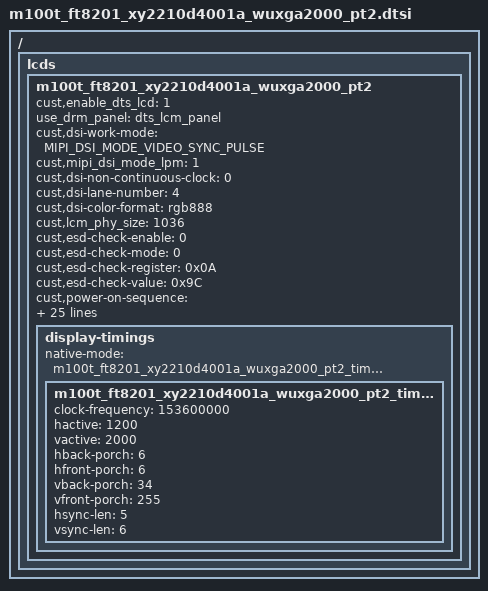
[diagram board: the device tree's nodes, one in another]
#include <dt-bindings/display/cust_drm.h>

/ {
	fragment {
		target-path = "/";
		__overlay__ {
			lcds {
				m100t_ft8201_xy2210d4001a_wuxga2000_pt2: m100t_ft8201_xy2210d4001a_wuxga2000_pt2 {

					cust,enable_dts_lcd=<1>; //use lcd dts
					use_drm_panel="dts_lcm_panel";
					cust,dsi-work-mode = <MIPI_DSI_MODE_VIDEO_SYNC_PULSE>;
					cust,mipi_dsi_mode_lpm=<1>;
					cust,dsi-non-continuous-clock=<0>;
					cust,dsi-lane-number = <4>;
					cust,dsi-color-format = "rgb888";

					cust,lcm_phy_size=<1036>;
					/*cust,width-mm = <108>;
					cust,height-mm = <172>;*/

					cust,esd-check-enable = <0>;
					cust,esd-check-mode = <0>;
					cust,esd-check-register = <0x0A>;
					cust,esd-check-value = <0x9C>;

					/*<cust_gpio_type enable_level delay>*/
					cust,power-on-sequence = <CUST_GPIO_LCM_1V8 HIGH 10>,
											<CUST_GPIO_BIAS_POS HIGH 1>, 
											<CUST_GPIO_BIAS_NEG HIGH 20>,
											<CUST_GPIO_TP_RST LOW 1>,
											<CUST_GPIO_TP_RST HIGH 1>,
											<CUST_GPIO_LCM_RST HIGH 10>,
											<CUST_GPIO_LCM_RST LOW 2>,
											<CUST_GPIO_LCM_RST HIGH 5>;

					cust,power-on-sequence_after_cmd=<CUST_GPIO_BIAS_EN HIGH 0>;

					cust,power-off-sequence = <CUST_GPIO_BIAS_EN LOW 0>,
											<CUST_GPIO_TP_RST LOW 10>, 
											<CUST_GPIO_LCM_1V8 LOW 10>,
											<CUST_GPIO_BIAS_POS LOW 2>,
											<CUST_GPIO_BIAS_NEG LOW 0>;
											
					/*cust,power-off-sequence_before_cmd= <CUST_GPIO_BIAS_EN LOW 0>;*/
					
					/*dely SizeH SizeL Cmd Data */
					cust,initial-command = [
						00 02 50 5a 
						00 02 54 03 
						00 03 50 5a 03 
						00 02 80 ee 
						00 03 50 5a 08 
						00 03 80 c8 00 
						00 03 50 5a 09 
						00 11 80 5a 51 b5 2a 6c d5 4a 01 80 e0 cd f3 3c 0f 00 b7 
						00 11 90 00 3f 42 0a e3 6d db f0 91 5c 62 20 6b a1 26 00 
						00 07 a0 01 82 08 20 06 00 
						00 03 50 5a 0a 
						00 11 80 a5 4b 03 00 1c 30 48 5f 72 7c b1 b4 ef 4a 18 6a 
						00 11 90 43 43 36 2a 1c 16 17 00 1c 30 48 5f 72 7c b1 b4 
						00 0d a0 ef 4a 18 6a 43 43 36 2a 1c 16 03 00 
						00 03 50 5a 0b 
						00 11 80 00 00 20 44 08 00 60 47 00 00 10 22 04 00 b0 23 
						00 03 90 15 00 
						00 03 50 5a 0c 
						00 11 80 fe 68 58 82 3e 64 b8 06 00 60 15 00 50 15 56 51 
						00 11 90 15 55 61 15 00 60 15 00 50 15 56 51 15 55 61 95 
						00 11 a0 ab 18 00 05 00 05 00 05 80 4c 29 84 52 01 09 00 
						00 03 50 5a 0d 
						00 0f 80 f0 b1 71 ef 49 c0 80 1a 00 00 00 00 00 00 
						00 03 50 5a 0e 
						00 0d 80 ff 81 68 ec 22 6d 22 00 00 00 00 00 
						00 03 50 5a 0f 
						00 11 80 0d 08 4a 00 25 80 64 0c 51 11 c8 50 01 42 8c 8c 
						00 08 90 24 69 81 71 44 7c 14 
						00 03 50 5a 10 
						00 11 80 00 78 03 e7 1f 17 00 78 20 d3 d4 18 30 88 41 8a 
						00 10 90 39 28 a9 c5 9a 7b fa 07 7e e0 07 7e 20 10 00 
						00 03 50 5a 11 
						00 11 80 46 77 03 40 ca f3 ff 83 30 08 c4 06 a1 d8 24 18 
						00 11 90 30 c6 66 c1 80 31 15 cb e5 d2 68 6c 36 1d 04 c8 
						00 11 a0 b0 d9 88 60 b0 81 40 1a 1b 48 63 03 b9 00 1c 80 
						00 11 b0 50 30 00 e0 e1 01 00 28 0e 06 43 55 55 55 55 55 
						00 11 c0 95 88 88 88 88 88 c8 08 86 c6 e3 81 00 20 00 21 
						00 11 d0 42 88 00 00 00 00 40 00 00 31 04 41 06 00 00 00 
						00 11 e0 00 00 00 00 00 00 00 00 00 00 92 04 00 85 11 0c 
						00 0a f0 00 00 40 00 00 00 00 5e 00 
						00 03 50 5a 12 
						00 11 80 00 00 00 00 00 00 00 00 00 00 00 00 00 00 00 00 
						00 0a 90 00 00 00 00 00 00 00 74 00 
						00 03 50 5a 13 
						00 11 80 01 00 00 0c 00 00 00 00 01 02 01 01 44 0c ce e7 
						00 04 90 62 06 00 
						00 03 50 5a 14 
						00 11 80 d1 00 40 5e e9 ef f7 fb fd 7e 01 00 00 f4 c5 41 
						00 11 90 88 1c 60 0e 42 e4 00 9b 10 22 07 80 8b 10 39 80 
						00 11 a0 39 e4 c8 08 cc 80 21 45 00 00 00 00 00 00 00 00 
						00 11 b0 00 00 00 00 00 00 10 00 00 ec be e8 1b 00 40 a1 
						00 11 c0 50 b8 01 21 72 80 31 00 37 21 44 0e 30 06 e0 46 
						00 11 d0 84 c8 01 c6 00 dc 8c 10 39 c0 18 80 1b 12 22 07 
						00 11 e0 18 03 70 53 42 e4 00 63 00 dc 04 8e 1c 60 0c 80 
						00 11 f0 7b c0 91 07 8c 01 18 01 bf 5f 08 00 00 00 00 00 
						00 03 50 5a 15 
						00 11 80 00 00 00 00 00 00 00 00 00 00 00 00 52 d4 e0 e7 
						00 11 90 f3 00 e8 63 41 c8 80 86 60 40 1d 31 32 a0 21 18 
						00 11 a0 50 00 00 00 00 00 00 00 00 00 00 00 00 00 00 00 
						00 11 b0 00 00 00 00 00 00 00 40 13 00 f0 00 94 b6 6d db 
						00 11 c0 b6 6d db 95 92 3e 4e 41 0c 42 00 a0 b6 6d db b6 
						00 11 d0 6d db b6 5d ab e8 e3 82 a1 38 92 65 6a db b6 6d 
						00 11 e0 db b6 6d db b5 9a 3e 6e 49 8e 62 08 a2 b6 6d db 
						00 11 f0 b6 6d db b6 5d 29 e8 e3 00 81 30 10 45 6a 5b 00 
						00 03 50 5a 16 
						00 11 80 00 00 00 00 00 00 00 00 00 00 00 00 00 00 00 00 
						00 07 90 00 00 00 00 90 40 
						00 03 50 5a 18 
						00 11 80 ef bd f7 de 7b ef bd 07 08 08 0a 0c 0c 0c 0c 0c 
						00 11 90 0c 0c 0c 5c 09 a8 aa aa aa aa aa aa aa aa aa 5a 
						00 11 a0 59 59 59 59 59 59 59 59 59 59 59 09 04 ff 05 80 
						00 10 b0 80 00 04 20 00 01 08 40 00 02 10 80 00 04 0f 
						00 03 50 5a 19 
						00 11 80 eb d6 b9 b3 a8 9d 98 91 8c 87 84 82 66 f6 ff ff 
						00 11 90 ff ff ff ff ff 7f 0f 0f af b5 71 0e 6c 4a 69 08 
						00 08 a0 00 04 62 00 00 00 00 
						00 03 50 5a 1a 
						00 11 80 00 04 08 0c 00 10 14 18 1c 00 20 28 30 38 00 3f 
						00 11 90 47 4f 57 ff 5f 67 6f 77 aa 7f 87 8f 97 aa 9f a7 
						00 11 a0 af b7 ff bf c7 d0 d8 0f e0 e8 f0 f8 00 fc fe ff 
						00 11 b0 00 00 03 07 0b bc 0f 13 17 1b 16 1f 26 2e 36 6c 
						00 11 c0 3e 45 4d 55 6c 5d 65 6c 74 b0 7c 84 8b 93 b1 9b 
						00 11 d0 a3 aa b2 61 ba c1 c9 d1 6c d9 e0 e8 f0 6c f4 f6 
						00 11 e0 f7 00 00 03 07 0b ac 0f 13 16 1a b1 1e 26 2d 35 
						00 11 f0 21 3c 44 4b 53 77 5b 62 6a 71 88 79 80 88 90 1d 
						00 03 50 5a 1b 
						00 11 80 97 9f a6 ae 72 b6 bd c5 cd 1c d4 dc e4 ec 5b f0 
						00 05 90 f2 f3 15 00 
						00 03 50 5a 20 
						00 08 80 90 00 00 00 00 00 00 
						00 03 50 5a 22 
						00 0e 80 2d d3 00 41 10 04 41 10 04 41 10 1e 00 
						00 03 50 5a 23 
						00 11 80 01 05 00 05 00 00 00 00 00 00 00 00 00 00 00 00 
						00 0a 90 ff 0f 00 00 2c 00 00 00 00 
						00 03 50 5a 24 
						00 11 80 00 03 00 9d bf 10 00 00 00 00 00 00 00 00 77 62 
						00 02 90 a5 
						00 03 50 5a 2f 
						00 02 09 01

						78 02 11 00
						0A 02 29 00
						];
					cust,sleep-in-command = [
						0A 01 28 
						78 01 10
						];
					cust,sleep-out-command = [
						78 01 11
						64 01 29
						];

					cust,pll_clk = <547>;
					cust,data_rate = <1076>;
					cust,rotate = <1>;
					cust,ssc_enable = <0>;
					cust,fps = <60>;

					display-timings {
						native-mode = <&m100t_ft8201_xy2210d4001a_wuxga2000_pt2_timing>;

						m100t_ft8201_xy2210d4001a_wuxga2000_pt2_timing: timing0 {
							clock-frequency = <153600000>; /*no need to modify,but can`t delete*/
							hactive = <1200>;
							vactive = <2000>;
							hback-porch = <6>;
							hfront-porch = <6>;
							vback-porch = <34>;
							vfront-porch = <255>;
							hsync-len = <5>;
							vsync-len = <6>;
						};
					};
				};
			};
		};
	};
};

